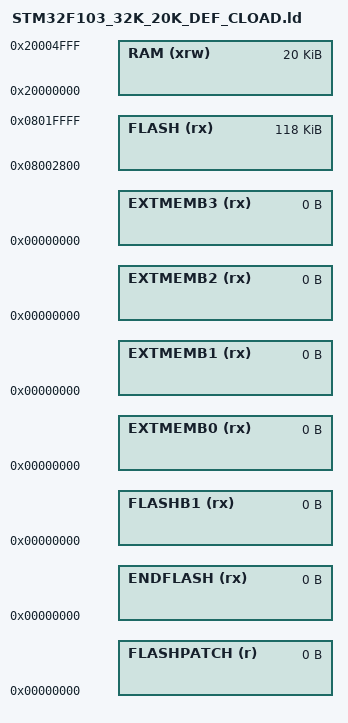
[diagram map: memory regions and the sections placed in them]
/*
Linker subscript for STM32F103 definitions with 32K Flash and 20K RAM
Copyright RAISONANCE 2007-2009
!!! This file is automatically generated by Ride !!!
Do not modify it, as it will be erased at every link.
You can use, copy and distribute this file freely, but without any waranty.
*/

/* Memory Spaces Definitions */

MEMORY
{
  RAM (xrw) : ORIGIN = 0x20000000, LENGTH = 20K
  FLASH (rx) : ORIGIN = 0x8002800, LENGTH = 118K
  FLASHPATCH (r) : ORIGIN = 0x00000000, LENGTH = 0
  ENDFLASH (rx)  : ORIGIN = 0x00000000, LENGTH = 0
  FLASHB1  (rx)  : ORIGIN = 0x00000000, LENGTH = 0
  EXTMEMB0 (rx)  : ORIGIN = 0x00000000, LENGTH = 0
  EXTMEMB1 (rx)  : ORIGIN = 0x00000000, LENGTH = 0
  EXTMEMB2 (rx)  : ORIGIN = 0x00000000, LENGTH = 0
  EXTMEMB3 (rx)  : ORIGIN = 0x00000000, LENGTH = 0
}

/* higher address of the user mode stack */
_estack = 0x20005000;

